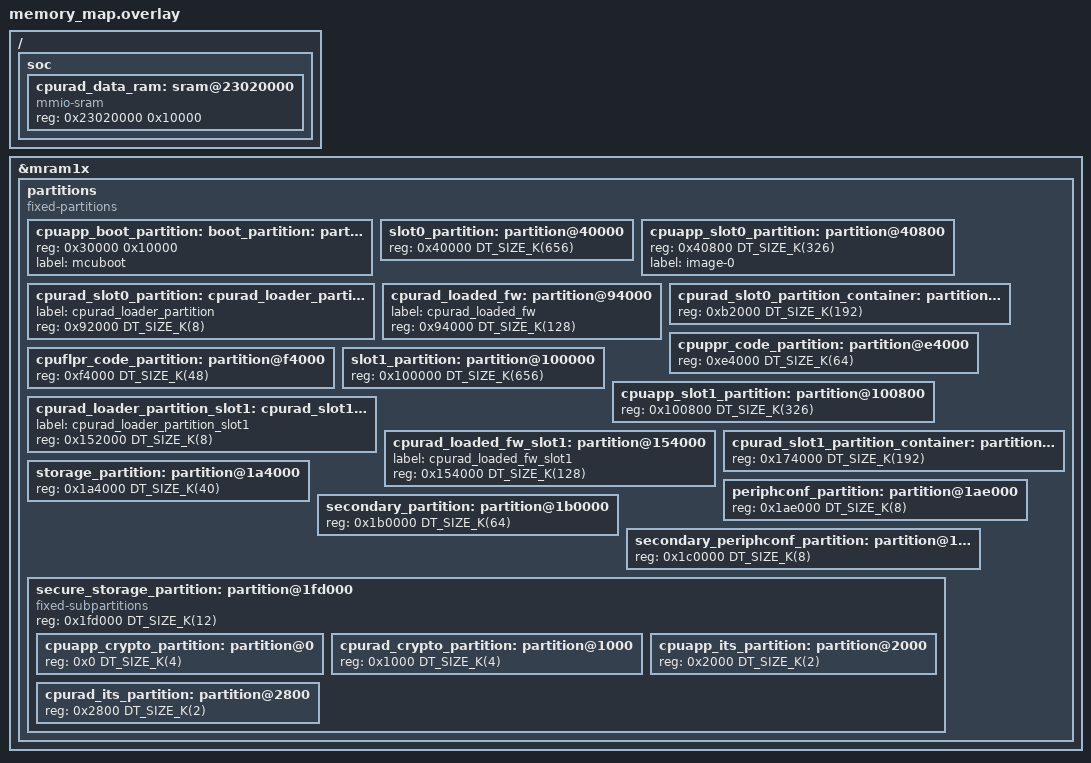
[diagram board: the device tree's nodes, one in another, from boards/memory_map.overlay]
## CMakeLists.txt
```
#
# Copyright (c) 2025 Nordic Semiconductor ASA
#
# SPDX-License-Identifier: LicenseRef-Nordic-5-Clause
#

cmake_minimum_required(VERSION 3.20.0)

find_package(Zephyr REQUIRED HINTS $ENV{ZEPHYR_BASE})

if(NOT SYSBUILD)
  message(FATAL_ERROR
    " This is a multi-image application that should be built using sysbuild.\n"
    " Add --sysbuild argument to west build command to prepare all the images.")
endif()

project(idle_relocated_tcm)

target_sources(app PRIVATE src/main.c)
```

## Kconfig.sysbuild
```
#
# Copyright (c) 2025 Nordic Semiconductor ASA
#
# SPDX-License-Identifier: LicenseRef-Nordic-5-Clause
#

choice NETCORE
	default NETCORE_REMOTE

config NETCORE_REMOTE
	bool "Remote radio"
	help
	  Use remote radio.

endchoice

config NETCORE_IMAGE_NAME
	default "remote" if NETCORE_REMOTE

config NETCORE_IMAGE_PATH
	default "$(ZEPHYR_NRF_MODULE_DIR)/samples/nrf54h20/idle_relocated_tcm/remote" if NETCORE_REMOTE

source "share/sysbuild/Kconfig"
```

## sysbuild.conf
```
#
# Copyright (c) 2025 Nordic Semiconductor ASA
#
# SPDX-License-Identifier: LicenseRef-Nordic-5-Clause
#

# This automatically adds the radio_loader application to the build
SB_CONFIG_NRF_RADIO_LOADER=y
SB_CONFIG_NETCORE_REMOTE=y

SB_CONFIG_BOOTLOADER_MCUBOOT=y
SB_CONFIG_MCUBOOT_MODE_DIRECT_XIP=y
SB_CONFIG_BOOT_SIGNATURE_TYPE_ED25519=y
SB_CONFIG_BOOT_SIGNATURE_TYPE_PURE=y
# Reserve space for MCUboot trailer in CPURAD slots
SB_CONFIG_MCUBOOT_IMAGES_ROM_END_OFFSET_AUTO="remote;remote_secondary_app"
```

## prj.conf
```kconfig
#
# Copyright (c) 2025 Nordic Semiconductor ASA
#
# SPDX-License-Identifier: LicenseRef-Nordic-5-Clause
#

CONFIG_LOG=y

CONFIG_SOC_NRF54H20_CPURAD_ENABLE=y

# Enable S2RAM
CONFIG_PM=y
CONFIG_PM_DEVICE=y
CONFIG_PM_DEVICE_RUNTIME=y
CONFIG_POWEROFF=y

# Set the version number for the firmware to verify dfu process
#CONFIG_MCUBOOT_IMGTOOL_SIGN_VERSION="0.0.1+0"
```

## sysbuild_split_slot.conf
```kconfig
#
# Copyright (c) 2025 Nordic Semiconductor ASA
#
# SPDX-License-Identifier: LicenseRef-Nordic-5-Clause
#

# This automatically adds the radio_loader application to the build
SB_CONFIG_NRF_RADIO_LOADER=y
SB_CONFIG_NETCORE_REMOTE=y

SB_CONFIG_BOOTLOADER_MCUBOOT=y
SB_CONFIG_MCUBOOT_MODE_DIRECT_XIP=y
SB_CONFIG_BOOT_SIGNATURE_TYPE_ED25519=y
SB_CONFIG_BOOT_SIGNATURE_TYPE_PURE=y

# Disable merging of slots -> use separate slots for each image
SB_CONFIG_MCUBOOT_SIGN_MERGED_BINARY=n

# Enable manifest-based updates
SB_CONFIG_MCUBOOT_MANIFEST_UPDATES=y
```

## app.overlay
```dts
/*
 * Copyright (c) 2025 Nordic Semiconductor ASA
 *
 * SPDX-License-Identifier: LicenseRef-Nordic-5-Clause
 */

#include "common/memory_map.dtsi"

&cpuapp_data {
	reg = <0x2f000000 0x39000>;
};

secondary_app_partition: &cpuapp_slot1_partition {};
```

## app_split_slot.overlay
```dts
/*
 * Copyright (c) 2025 Nordic Semiconductor ASA
 *
 * SPDX-License-Identifier: LicenseRef-Nordic-5-Clause
 */

#include "common/memory_map_split_slot.dtsi"

&cpuapp_data {
	reg = <0x2f000000 0x39000>;
};

secondary_app_partition: &cpuapp_slot1_partition {};
```

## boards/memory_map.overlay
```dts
/*
 * Copyright (c) 2025 Nordic Semiconductor ASA
 *
 * SPDX-License-Identifier: LicenseRef-Nordic-5-Clause
 */

/{
	soc{
		cpurad_data_ram: sram@23020000 {
			compatible = "mmio-sram";
			reg = < 0x23020000 0x10000 >;
			#address-cells = < 0x1 >;
			#size-cells = < 0x1 >;
			ranges = < 0x0 0x23020000 0x10000 >;
		};
	};
};

&mram1x {
	/delete-node/ partitions;

	/* Redefine the "partitions" DTS node. */
	partitions {
		compatible = "fixed-partitions";
		#address-cells = <1>;
		#size-cells = <1>;

		cpuapp_boot_partition: boot_partition: partition@30000 {
			reg = < 0x30000 0x10000 >;
			label = "mcuboot";
		};

		slot0_partition: partition@40000 {
			reg = <0x40000 DT_SIZE_K(656)>;
		};

		cpuapp_slot0_partition: partition@40800 {
			reg = <0x40800 DT_SIZE_K(326)>;
			label = "image-0";
		};

		cpurad_slot0_partition: cpurad_loader_partition: partition@92000 {
			label = "cpurad_loader_partition";
			reg = <0x92000 DT_SIZE_K(8)>;  /* 8 KB allocated (~4 KB actual) */
		};

		/* Remote firmware location in MRAM (fixed size for memcpy) */
		cpurad_loaded_fw: partition@94000 {
			label = "cpurad_loaded_fw";
			reg = <0x94000 DT_SIZE_K(128)>;  /* 128 KB fixed */
		};

		cpurad_slot0_partition_container: partition@b2000 {
			reg = <0xb2000 DT_SIZE_K(192)>; /* 238 - 128 - 8 = 192 KB allocated */
		};

		cpuppr_code_partition: partition@e4000 {
			reg = <0xe4000 DT_SIZE_K(64)>;
		};

		cpuflpr_code_partition: partition@f4000 {
			reg = <0xf4000 DT_SIZE_K(48)>;
		};

		slot1_partition: partition@100000 {
			reg = <0x100000 DT_SIZE_K(656)>;
		};

		cpuapp_slot1_partition: partition@100800 {
			reg = <0x100800 DT_SIZE_K(326)>;
		};

		cpurad_loader_partition_slot1: cpurad_slot1_partition: partition@152000 {
			label = "cpurad_loader_partition_slot1";
			reg = <0x152000 DT_SIZE_K(8)>;  /* 8 KB allocated (~4 KB actual) */
		};

		/* Remote firmware location in MRAM (fixed size for memcpy) */
		cpurad_loaded_fw_slot1: partition@154000 {
			label = "cpurad_loaded_fw_slot1";
			reg = <0x154000 DT_SIZE_K(128)>;  /* 128 KB fixed */
		};

		cpurad_slot1_partition_container: partition@174000 {
			reg = <0x174000 DT_SIZE_K(192)>; /* 238 - 128 - 8 = 192 KB allocated */
		};

		storage_partition: partition@1a4000 {
			reg = <0x1a4000 DT_SIZE_K(40)>;
		};

		periphconf_partition: partition@1ae000 {
			reg = <0x1ae000 DT_SIZE_K(8)>;
		};

		secondary_partition: partition@1b0000 {
			reg = <0x1b0000 DT_SIZE_K(64)>;
		};

		secondary_periphconf_partition: partition@1c0000 {
			reg = <0x1c0000 DT_SIZE_K(8)>;
		};

		/* NB: A gap has been left here for future partitions */

		/* 0x1fd000 was chosen for secure_storage_partition such that
		 * there is no more space after secure_storage_partition.
		 */
		secure_storage_partition: partition@1fd000 {
			compatible = "fixed-subpartitions";
			reg = <0x1fd000 DT_SIZE_K(12)>;
			ranges = <0x0 0x1fd000 0x3000>;
			#address-cells = <1>;
			#size-cells = <1>;

			cpuapp_crypto_partition: partition@0 {
				reg = <0x0 DT_SIZE_K(4)>;
			};

			cpurad_crypto_partition: partition@1000 {
				reg = <0x1000 DT_SIZE_K(4)>;
			};

			cpuapp_its_partition: partition@2000 {
				reg = <0x2000 DT_SIZE_K(2)>;
			};

			cpurad_its_partition: partition@2800 {
				reg = <0x2800 DT_SIZE_K(2)>;
			};
		};
	};
};
```

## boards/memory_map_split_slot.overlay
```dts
/*
 * Copyright (c) 2025 Nordic Semiconductor ASA
 *
 * SPDX-License-Identifier: LicenseRef-Nordic-5-Clause
 */

/{
	soc{
		cpurad_data_ram: sram@23020000 {
			compatible = "mmio-sram";
			reg = < 0x23020000 0x10000 >;
			#address-cells = < 0x1 >;
			#size-cells = < 0x1 >;
			ranges = < 0x0 0x23020000 0x10000 >;
		};
	};
};

&mram1x {
	/delete-node/ partitions;

	/* Redefine the "partitions" DTS node. */
	partitions {
		compatible = "fixed-partitions";
		#address-cells = <1>;
		#size-cells = <1>;

		cpuapp_boot_partition: boot_partition: partition@30000 {
			reg = < 0x30000 0x10000 >;
			label = "mcuboot";
		};

		/* Image 0: Application Core (primary slot) - main app */
		slot0_partition:cpuapp_slot0_partition: partition@40000 {
			reg = <0x40000 DT_SIZE_K(326)>;
		};

		/* Image 2: Radio Core (secondary slot) - radio loader */
		slot4_partition: cpurad_slot0_partition: cpurad_loader_partition:
		partition@92000 {
			label = "cpurad_loader_partition";
			reg = <0x92000 DT_SIZE_K(8)>;  /* 8 KB allocated (~4 KB actual) */
		};

		/* Image 1: Radio Core (primary slot) - remote firmware location in MRAM
		   (fixed size for memcpy
		 */
		slot2_partition: cpurad_loaded_fw: partition@94000 {
			label = "cpurad_loaded_fw";
			reg = <0x94000 DT_SIZE_K(128)>;  /* 128 KB fixed */
		};

		cpuppr_code_partition: partition@e4000 {
			reg = <0xe4000 DT_SIZE_K(64)>;
		};

		cpuflpr_code_partition: partition@f4000 {
			reg = <0xf4000 DT_SIZE_K(48)>;
		};

		/* Image 0: Application Core (secondary slot) - main app */
		slot1_partition: cpuapp_slot1_partition: partition@100000 {
			reg = <0x100000 DT_SIZE_K(326)>;
		};

		/* Image 2: Radio Core (secondary slot) - radio loader */
		slot5_partition: cpurad_slot1_partition: cpurad_loader_partition_slot1:
		partition@152000 {
			label = "cpurad_loader_partition_slot1";
			reg = <0x152000 DT_SIZE_K(8)>;  /* 8 KB allocated (~4 KB actual) */
		};

		/* Image 1: Radio Core (secondary slot) - remote firmware location in MRAM
		   (fixed size for memcpy)
		 */
		slot3_partition: cpurad_loaded_fw_slot1: partition@154000 {
			label = "cpurad_loaded_fw_slot1";
			reg = <0x154000 DT_SIZE_K(128)>;  /* 128 KB fixed */
		};

		storage_partition: partition@1a4000 {
			reg = <0x1a4000 DT_SIZE_K(40)>;
		};

		periphconf_partition: partition@1ae000 {
			reg = <0x1ae000 DT_SIZE_K(8)>;
		};

		secondary_partition: partition@1b0000 {
			reg = <0x1b0000 DT_SIZE_K(64)>;
		};

		secondary_periphconf_partition: partition@1c0000 {
			reg = <0x1c0000 DT_SIZE_K(8)>;
		};

		/* NB: A gap has been left here for future partitions */

		/* 0x1fd000 was chosen for secure_storage_partition such that
		 * there is no more space after secure_storage_partition.
		 */
		secure_storage_partition: partition@1fd000 {
			compatible = "fixed-subpartitions";
			reg = <0x1fd000 DT_SIZE_K(12)>;
			ranges = <0x0 0x1fd000 0x3000>;
			#address-cells = <1>;
			#size-cells = <1>;

			cpuapp_crypto_partition: partition@0 {
				reg = <0x0 DT_SIZE_K(4)>;
			};

			cpurad_crypto_partition: partition@1000 {
				reg = <0x1000 DT_SIZE_K(4)>;
			};

			cpuapp_its_partition: partition@2000 {
				reg = <0x2000 DT_SIZE_K(2)>;
			};

			cpurad_its_partition: partition@2800 {
				reg = <0x2800 DT_SIZE_K(2)>;
			};
		};
	};
};
```

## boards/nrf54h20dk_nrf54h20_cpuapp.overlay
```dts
/*
 * Copyright (c) 2025 Nordic Semiconductor ASA
 *
 * SPDX-License-Identifier: LicenseRef-Nordic-5-Clause
 */

#include "memory_map.overlay"

&cpuapp_data {
	reg = <0x2f000000 0x40000>;
};

secondary_app_partition: &cpuapp_slot1_partition {};
```

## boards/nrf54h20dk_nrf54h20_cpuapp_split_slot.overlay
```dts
/*
 * Copyright (c) 2025 Nordic Semiconductor ASA
 *
 * SPDX-License-Identifier: LicenseRef-Nordic-5-Clause
 */

#include "memory_map_split_slot.overlay"

&cpuapp_data {
	reg = <0x2f000000 0x40000>;
};

secondary_app_partition: &cpuapp_slot1_partition {};
```

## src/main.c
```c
/*
 * Copyright (c) 2025 Nordic Semiconductor ASA
 *
 * SPDX-License-Identifier: LicenseRef-Nordic-5-Clause
 */

#include <zephyr/kernel.h>
#include <zephyr/logging/log.h>

LOG_MODULE_REGISTER(idle);

int main(void)
{
	unsigned int cnt = 0;

	LOG_INF("Multicore idle test on %s", CONFIG_BOARD_TARGET);

	/* Using __TIME__ ensure that a new binary will be built on every
	 * compile which is convenient when testing firmware upgrade.
	 */
	LOG_INF("build time: " __DATE__ " " __TIME__);

	while (1) {
		LOG_INF("Multicore idle test iteration %u", cnt++);
		k_msleep(2000);
	}

	return 0;
}
```
